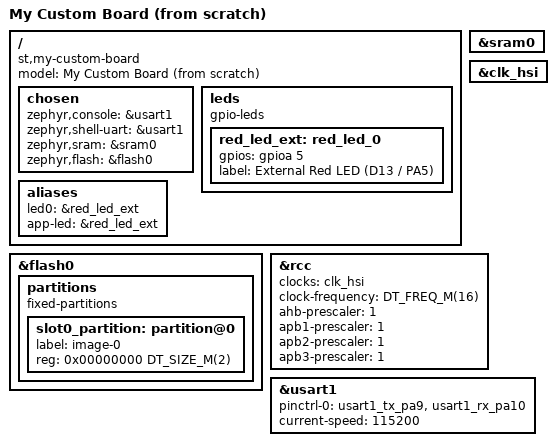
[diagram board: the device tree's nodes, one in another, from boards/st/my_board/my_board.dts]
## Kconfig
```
menuconfig LED_SUBSYSTEM
    bool "LED Subsystem"
    default y
    help
        Enable the LED subsystem configuration menu.

if LED_SUBSYSTEM

choice
    prompt "LED blink sleep time"
    default LED_BLINK_SLEEP_1S
    help
        Select the LED blink delay preset.
config LED_BLINK_SLEEP_15MS
    bool "15ms very fast"

config LED_BLINK_SLEEP_250MS
    bool "250ms (fast)"

config LED_BLINK_SLEEP_500MS
    bool "500ms"

config LED_BLINK_SLEEP_1S
    bool "1s (medium)"

config LED_BLINK_SLEEP_2S
    bool "2s (slow)"

endchoice

config LED_BLINK_SLEEP_TIME_MS
    int
    default 15 if LED_BLINK_SLEEP_15MS
    default 250 if LED_BLINK_SLEEP_250MS
    default 500 if LED_BLINK_SLEEP_500MS
    default 1000 if LED_BLINK_SLEEP_1S
    default 2000 if LED_BLINK_SLEEP_2S
    help
        Hidden integer value derived from the selected blink sleep preset.

menuconfig ADVANCED_LED_SETTINGS
    bool "Advanced LED settings"
    help
        Enable access to advanced LED tuning options.

if ADVANCED_LED_SETTINGS

config LED_BRIGHTNESS
    int "LED brightness"
    default 100
    range 0 100
    help
        LED brightness percentage.

config LED_FADE_DURATION_MS
    int "LED fade duration (ms)"
    default 500
    range 0 5000
    help
        Fade duration in milliseconds.

menu "Expert settings"
    visible if ADVANCED_LED_SETTINGS

config LED_DEBUG
    bool "Enable LED debugging"

config LED_CUSTOM_BLINK_PATTERN
    bool "Custom blink pattern"

endmenu

endif

endif

config APP_HEARTBEAT_PERIOD_MS
    int "Heartbeat LED period in milliseconds"
    default 500
    range 100 2000
    help
      Controls the blink period of the heartbeat LED in milliseconds.

source "Kconfig.zephyr"
```

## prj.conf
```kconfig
CONFIG_GPIO=y
CONFIG_LOG=y

CONFIG_LED_BLINK_SLEEP_1S=y
```

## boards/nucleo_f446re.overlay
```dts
/*
 * Board overlay for Nucleo F446RE — Lesson 4 Task 1
 *
 * The Nucleo F446RE has one built-in green LED (LD2) on PA5, already
 * exposed by the board DTS as the `led0` alias.  For this exercise an
 * external red LED is wired to the D12 header pin (PA6) to demonstrate
 * configurable heartbeat blinking via Kconfig.  We leave the board's
 * `led0` / green LED untouched and introduce a dedicated `app-led` alias
 * that the application code resolves with DT_ALIAS(app_led).
 */

/ {
	leds {
		compatible = "gpio-leds";

		/* External red LED connected to D12 (PA6) */
		red_led: red_led_0 {
			gpios = <&gpioa 6 GPIO_ACTIVE_HIGH>;
			label = "External Red LED (D12 / PA6)";
		};
	};

	aliases {
		app-led = &red_led;
	};
};
```

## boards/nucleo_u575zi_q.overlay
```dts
/*
 * Board overlay for Nucleo U575ZI-Q
 *
 * The Nucleo U575ZI-Q has built-in user LEDs exposed by the board DTS.
 * For this exercise an external red LED is wired to the D12 header pin
 * (PA6), matching the Nucleo F446RE wiring. We introduce a dedicated
 * `app-led` alias that the application code resolves with DT_ALIAS(app_led).
 */

/ {
	leds {
		compatible = "gpio-leds";

		/* External red LED connected to D12 (PA6) */
		red_led: red_led_0 {
			gpios = <&gpioa 6 GPIO_ACTIVE_HIGH>;
			label = "External Red LED (D12 / PA6)";
		};
	};

	aliases {
		app-led = &red_led;
	};
};
```

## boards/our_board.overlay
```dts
/*
 * Board overlay for our_board
 *
 * Use the on-board green user LED (LD1, PC7) as the heartbeat LED.
 * green_led_1 is already declared in our_board-common.dtsi; we just
 * expose it under the application's `app-led` alias so main.cpp can
 * resolve it via DT_ALIAS(app_led).
 */

/ {
	aliases {
		app-led = &green_led_1;
	};
};
```

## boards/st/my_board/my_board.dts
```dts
/*
 * SPDX-License-Identifier: Apache-2.0
 *
 * From-scratch board for STM32U575ZI on the Nucleo-U575ZI-Q.
 * Minimal: HSI16 clock, USART1 console, one external red LED on PA5/D13.
 *
 * Memory layout (inherited from <st/u5/stm32u575Xi.dtsi>):
 *   FLASH (flash0) : 0x08000000, 2 MB
 *   SRAM  (sram0)  : 0x20000000, 768 KB (main SRAM region)
 */

/dts-v1/;
#include <st/u5/stm32u575Xi.dtsi>
#include <st/u5/stm32u575zitxq-pinctrl.dtsi>

/ {
	model = "My Custom Board (from scratch)";
	compatible = "st,my-custom-board";

	chosen {
		zephyr,console = &usart1;
		zephyr,shell-uart = &usart1;
		zephyr,sram = &sram0;     /* main SRAM, 768 KB @ 0x20000000 */
		zephyr,flash = &flash0;   /* internal flash, 2 MB @ 0x08000000 */
	};

	leds {
		compatible = "gpio-leds";

		red_led_ext: red_led_0 {
			gpios = <&gpioa 5 GPIO_ACTIVE_HIGH>;
			label = "External Red LED (D13 / PA5)";
		};
	};

	aliases {
		led0    = &red_led_ext;
		app-led = &red_led_ext;   /* matches DT_ALIAS(app_led) in main.cpp */
	};
};

/* Make memory regions explicit (status=okay is the default in the SoC
 * dtsi; we re-state here for clarity). The sizes come from the SoC
 * include and must NOT be hand-edited — they are silicon facts.
 */
&sram0 {
	status = "okay";
};

&flash0 {
	status = "okay";

	/* A single-image flash layout: the whole 2 MB belongs to the app.
	 * Add MCUboot partitions here later if doing firmware updates.
	 */
	partitions {
		compatible = "fixed-partitions";
		#address-cells = <1>;
		#size-cells = <1>;

		slot0_partition: partition@0 {
			label = "image-0";
			reg = <0x00000000 DT_SIZE_M(2)>;
		};
	};
};

/* System clock: HSI16 (16 MHz internal RC) — no PLL, no LSE.
 * Trades performance for simplicity; UART at 115200 still works fine.
 */
&clk_hsi {
	status = "okay";
};

&rcc {
	clocks = <&clk_hsi>;
	clock-frequency = <DT_FREQ_M(16)>;
	ahb-prescaler = <1>;
	apb1-prescaler = <1>;
	apb2-prescaler = <1>;
	apb3-prescaler = <1>;
};

/* Console UART — same physical pins as nucleo (PA9/PA10) so the
 * Nucleo's on-board ST-LINK VCP forwards the bytes to USB.
 */
&usart1 {
	pinctrl-0 = <&usart1_tx_pa9 &usart1_rx_pa10>;
	pinctrl-names = "default";
	current-speed = <115200>;
	status = "okay";
};
```

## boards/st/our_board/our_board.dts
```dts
/*
 * Copyright (c) 2021 Linaro Limited
 *
 * SPDX-License-Identifier: Apache-2.0
 */

/dts-v1/;
#include "our_board-common.dtsi"

/ {
	model = "STMicroelectronics STM32U575ZI-NUCLEO-Q board";
	compatible = "st,stm32u575zi-nucleo-q";

	#address-cells = <1>;
	#size-cells = <1>;

	chosen {
		zephyr,console = &usart1;
		zephyr,shell-uart = &usart1;
		zephyr,sram = &sram0;
		zephyr,flash = &flash0;
		zephyr,canbus = &fdcan1;
	};

	aliases {
		led0 = &blue_led_1;
		sw0 = &user_button;
		pwm-led0 = &pwm_led_1;
		pwm-led1 = &pwm_led_2;
		watchdog0 = &iwdg;
		volt-sensor0 = &vref1;
		volt-sensor1 = &vbat4;
		die-temp0 = &die_temp;
	};
};

&usart1 {
	pinctrl-0 = <&usart1_tx_pa9 &usart1_rx_pa10>;
	pinctrl-names = "default";
	current-speed = <115200>;
	status = "okay";
};

&gpdma1 {
	status = "okay";
};

&die_temp {
	status = "okay";
};
```

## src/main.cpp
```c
#include <zephyr/drivers/gpio.h>
#include <zephyr/init.h>
#include <zephyr/kernel.h>
#include <zephyr/logging/log.h>

/* Resolve the external heartbeat LED via its devicetree alias. */
static const struct gpio_dt_spec led =
    GPIO_DT_SPEC_GET(DT_ALIAS(app_led), gpios);

LOG_MODULE_REGISTER(main, LOG_LEVEL_INF);

/* Runs at APPLICATION init level — after the console driver is up but
 * before main() is invoked. This is the canonical Zephyr way to perform
 * board-level bring-up announcements.
 */
static int board_announce(void)
{
    printk("Board Initialized\n");
    return 0;
}
SYS_INIT(board_announce, APPLICATION, CONFIG_APPLICATION_INIT_PRIORITY);

int main(void)
{
    int ret;

    if (!gpio_is_ready_dt(&led)) {
        LOG_ERR("Heartbeat LED GPIO controller is not ready");
        return 0;
    }

    ret = gpio_pin_configure_dt(&led, GPIO_OUTPUT_ACTIVE);
    if (ret < 0) {
        LOG_ERR("Failed to configure heartbeat LED pin: %d", ret);
        return 0;
    }

    LOG_INF("Heartbeat LED on port %s pin %d — period %d ms",
        led.port->name, led.pin, CONFIG_LED_BLINK_SLEEP_TIME_MS);

    while (1) {
        ret = gpio_pin_toggle_dt(&led);
        if (ret < 0) {
            LOG_ERR("Failed to toggle heartbeat LED pin: %d", ret);
            return 0;
        }

        k_msleep(CONFIG_LED_BLINK_SLEEP_TIME_MS);
    }

    return 0;
}
```
